# cm4 register map
Registers are 32-bit, read-write, no defined reset value unless marked. A register's access mark holds for its fields unless they carry their own. Offsets are from the block's base; lines under a group give offsets from that group; [hi:lo] are bit positions; {n}, {i} and the like mark numbered series; 'fields as' and 'values as' point back to an identical list; <NAME> marks a mode.

## Memory map
0xE0001000 DWT size 0x5C — Data Watchpoint Trace
0xE000E000 SCB size 0x8 — System control block
0xE000E010 SysTick size 0x10 — 24Bit System Tick Timer for use in RTOS
0xE000E100 NVIC size 0x350
0xE000ED00 Debug size 0x100
0xE000ED90 MPU size 0x30 — Memory Protection Unit

## NVIC
Base 0xE000E100
{0x0+4i} NVIC_ISER[{i}] (i=0..7) ro — Interrupt Set-Enable Registers
{0x80+4i} NVIC_ICER[{i}] (i=0..7) ro — Interrupt Clear-Enable Registers
{0x100+4i} NVIC_ISPR[{i}] (i=0..7) ro — Interrupt Set-Pending Registers
{0x180+4i} NVIC_ICPR[{i}] (i=0..7) ro — Interrupt Clear-Pending Registers
{0x200+4i} NVIC_IABR[{i}] (i=0..7) ro — Interrupt Active Bit Register
{0x300+4i} NVIC_IPR[{i}] (i=0..59) ro — Interrupt Priority Register
0xE00 STIR wo — Software Trigger Interrupt Register
  [8:0] INTID — Interrupt ID of the interrupt to trigger, in the range 0-239.

## SysTick — 24Bit System Tick Timer for use in RTOS
Base 0xE000E010; register names take the prefix SYST_
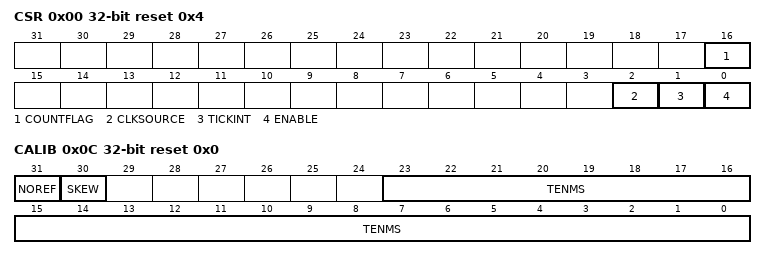
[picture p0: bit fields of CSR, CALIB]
0x00 CSR reset 0x4 — SysTick Control and Status Register
  [16] COUNTFLAG — SysTick counted to zero
  [2] CLKSOURCE — Source to count from
    0=External_Clk (External Clock); 1=CPU_Clk (CPU Clock)
  [1] TICKINT — Generate Tick Interrupt
    0=Disable (Counting down to zero asserts the SysTick exception request); 1=Enable (Counting down to zero does not assert the SysTick exception request)
  [0] ENABLE — Enable SysTick Timer
    0=Disable (counter disabled); 1=Enable (counter enabled)
0x04 RVR reset 0x0 — SysTick Reload Value Register
  [23:0] RELOAD — Value to auto reload SysTick after reaching zero
0x08 CVR reset 0x0 — SysTick Current Value Register
  [23:0] CURRENT — Current value
0x0C CALIB ro reset 0x0 — SysTick Calibration Value Register
  [31] NOREF
    0=Ref_Clk_Available; 1=Ref_Clk_Unavailable (Ref Clk not available)
  [30] SKEW — Clock Skew
    0=Exact (10ms calibration value is exact); 1=Inexact (10ms calibration value is inexact, because of the clock frequency)
  [23:0] TENMS — Reload value to use for 10ms timing

## MPU — Memory Protection Unit
Base 0xE000ED90; register names take the prefix MPU_
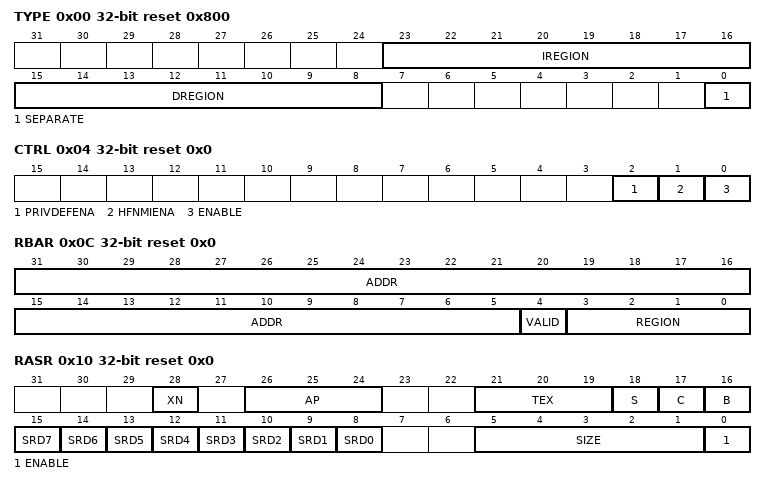
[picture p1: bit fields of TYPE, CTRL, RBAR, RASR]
0x00 TYPE ro reset 0x800 — MPU Type Register
  [23:16] IREGION — Indicates the number of supported MPU instruction regions. Always contains 0x0: the MPU memory map is unified and is described by the DREGION field.
  [15:8] DREGION — Indicates the number of supported MPU data regions depending on your implementation.
  [0] SEPARATE — Indicates support for unified or separate instruction and data memory maps.
    0=Unified (Only unified memory maps are supported.)
0x04 CTRL reset 0x0 — MPU Control Register
  [2] PRIVDEFENA — Enables privileged software access to the default memory map.
  [1] HFNMIENA — Enables the operation of MPU during hard fault, NMI, and FAULTMASK handlers.
  [0] ENABLE — Enables the optional MPU.
0x08 RNR reset 0x0 — MPU Region Number Register
  [7:0] REGION — Indicates the MPU region referenced by the MPU_RBAR and MPU_RASR registers.
0x0C RBAR reset 0x0 — MPU Region Base Address Register
  [31:5] ADDR — The ADDR field is bits[31:N] of the MPU_RBAR. The region size, as specified by the SIZE field in the MPU_RASR, defines the value of N: N = Log2(Region size in bytes). If the region size is configured to 4GB, in the MPU_RASR, there is no valid ADDR field. In this case, the region occupies the complete memory map, and the base address is 0x00000000. The base address is aligned to the size of the region. For example, a 64KB region must be aligned on a multiple of 64KB, for example, at 0x00010000 or 0x00020000.
  [4] VALID — MPU Region number valid bit. Depending on your implementation, this has the following effect: 0 - either updates the base address for the region specified by MPU_RNR or ignores the value of the REGION field. 1 - either updates the value of the MPU_RNR to the value of the REGION field or updates the base address for the region specified in the REGION field.
  [3:0] REGION — On Write, see the VALID field. On read, specifies the region number.
0x10 RASR reset 0x0 — MPU Region Base Attribute and Size Register
  [28] XN — Instruction access disable bit
    0=I_Enabled (Instruction fetches enabled.); 1=I_Disabled (Instruction fetches disabled.)
  [26:24] AP — Access permission field
    0=No_Access (All accesses generate a permission fault.); 1=Privileged_RW (Access from privileged software only.); 2=Unpriviledged_RO (Writes by unprivileged software generates a permission fault.); 3=Full_Access; 5=Privileged_RO (Reads by privileged software only.); 6=Read_Only by privileged or unprivileged software; 7=Read_Only by privileged or unprivileged software
  [21:19] TEX — Memory access attribute.
  [18] S — Shareable bit. Applies to Normal memory only.
  [17] C — Memory access attribute.
  [16] B — Memory access attribute.
  [15] SRD7 — Subregion disable bits.
  [14] SRD6 — Subregion disable bits.
  [13] SRD5 — Subregion disable bits.
  [n+8] SRD{n} (n=0..4) — Subregion disable bits
  [5:1] SIZE — Specifies the size of the MPU protection region. Minimum value is 4. The Region size is defined as (Region size in bytes) = 2^(SIZE+1)
  [0] ENABLE — Region enable bit.
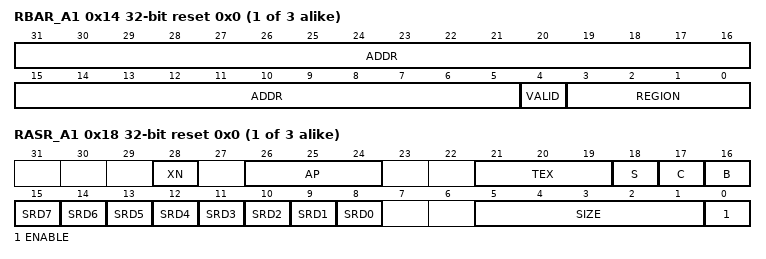
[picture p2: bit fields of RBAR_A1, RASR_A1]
{0xC+8i} RBAR_A{i} reset 0x0 (i=1..3) — Uses (MPU_RNR[7:2]<<2) + {i}
  fields as RBAR
{0x10+8i} RASR_A{i} reset 0x0 (i=1..3) — Uses (MPU_RNR[7:2]<<2) + {i}
  fields as RASR

## Notices in the file
Copyright (C) 2016 AdaCore
